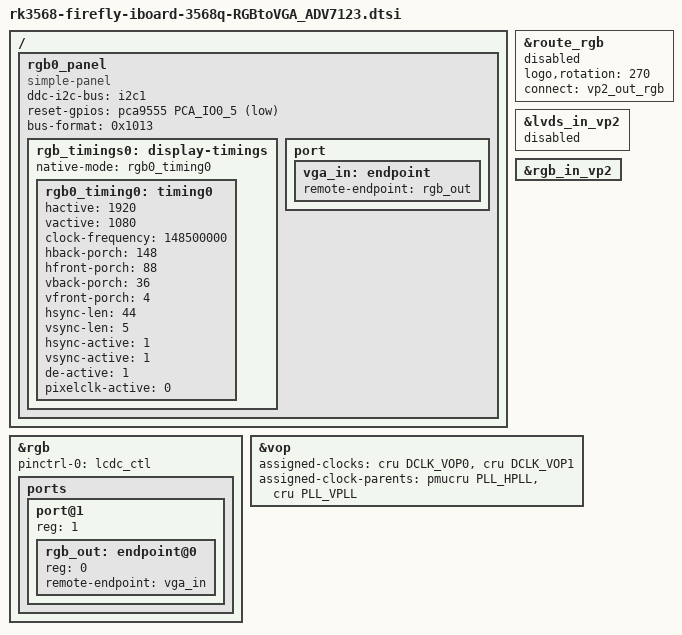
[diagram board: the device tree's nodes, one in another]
// SPDX-License-Identifier: (GPL-2.0+ OR MIT)
/*
 * Copyright (c) 2022 T-chip Firefly. 
 * Support ADV7123 RGB to VGA
 */


/ {

	rgb0_panel {
			status = "okay";
			compatible = "simple-panel";
			ddc-i2c-bus = <&i2c1>;
			//enable-gpios =<&pca9555 PCA_IO0_1 GPIO_ACTIVE_HIGH>;
			reset-gpios = <&pca9555 PCA_IO0_5 GPIO_ACTIVE_LOW>;
			/*	bus-format. default RGB for D23-D16/D15-8/D7-D0. 
			        MEDIA_BUS_FMT_RGB888_1X24,  0x100a
					MEDIA_BUS_FMT_BGR888_1X24,  0x1013
			*/
			bus-format = < 0x1013>;

			/*
				name              refresh     xres    yres    pixclock            h_bp    h_fp    v_bp    v_fp    h_pw    v_pw    polariry    PorI    flag(used for vic)
				{"640x480p@60Hz",   60,         640,    480,    25000000,   48,     16,     33,    10,       96,    2,      0,          0,      1   },
				{"800x600p@60Hz",   60,         800,    600,    40000000,   88,     40,     23,     1,      128,    4,      FB_SYNC_HOR_HIGH_ACT | FB_SYNC_VERT_HIGH_ACT,           0,      0       },
				{"1024x768p@60Hz",  60,         1024,   768,    65000000,   160,    24,     29,     3,      136,    6,      0,          0,      0   },
				{"1280x720p@60Hz",  60,         1280,   720,    74250000,   220,   110,     20,     5,       40,    5,      FB_SYNC_HOR_HIGH_ACT | FB_SYNC_VERT_HIGH_ACT,           0,      0       },
				{"1280x1024p@60Hz", 60,         1280,   1024,   108000000,  248,    48,     38,     1,      112,    3,      FB_SYNC_HOR_HIGH_ACT | FB_SYNC_VERT_HIGH_ACT,           0,      6       },
				{"1366x768p@60Hz",  60,         1366,   768,    85500000,   213,    70,     24,     3,      143,    3,      FB_SYNC_HOR_HIGH_ACT | FB_SYNC_VERT_HIGH_ACT,           0,      0       },
				{"1440x900p@60Hz",  60,         1440,   900,    106500000,  232,    80,     25,     3,      152,    6,      FB_SYNC_VERT_HIGH_ACT,          0,      0   },
				{"1600x900p@60Hz",  60,         1600,   900,    108000000,   96,    24,     96,     1,       80,    3,      FB_SYNC_VERT_HIGH_ACT | FB_SYNC_HOR_HIGH_ACT,           0,      0       },
				{"1680x1050p@60Hz", 60,         1680,   1050,   146200000,  280,    104,    30,     3,      176,    6,      FB_SYNC_VERT_HIGH_ACT,          0,      0   },
				{"1920x1080p@60Hz", 60,         1920,   1080,   148500000,  148,    88,     36,     4,       44,    5,      FB_SYNC_HOR_HIGH_ACT | FB_SYNC_VERT_HIGH_ACT,           0,      0       },
			*/
			rgb_timings0: display-timings {
				native-mode = <&rgb0_timing0>;
				rgb0_timing0: timing0 {
					hactive = <1920>;
					vactive = <1080>;
					clock-frequency = <148500000>;
					hback-porch = <148>; 
					hfront-porch = <88>;
					vback-porch = <36>;
					vfront-porch = <4>;
					hsync-len = <44>;   
					vsync-len = <5>;
					hsync-active = <1>;
					vsync-active = <1>;
					de-active = <1>;
					pixelclk-active = <0>;
				};
			};

			port {
				vga_in: endpoint {
					remote-endpoint = <&rgb_out>;
				};
			};
	};	

};

&route_rgb {
    status = "disabled";
    logo,rotation = <270>; //support rotation 90,180,270
    connect = <&vp2_out_rgb>;
};

&rgb {
	status = "okay";
	pinctrl-names = "default";
	pinctrl-0 = <&lcdc_ctl>;
	ports {
		port@1 {
			reg = <1>;
			#address-cells = <1>;
			#size-cells = <0>;

			rgb_out: endpoint@0 {
				reg = <0>;
				remote-endpoint = <&vga_in>;
			};
		};
	};
};

&lvds_in_vp2 {
	status = "disabled";
};

&rgb_in_vp2 {
	status = "okay";
};


//&route_hdmi {
//    status = "okay";
//    connect = <&vp0_out_hdmi>;
//};

&vop {
	        status = "okay";
			 assigned-clocks = <&cru DCLK_VOP0>, <&cru DCLK_VOP1>;
			        assigned-clock-parents = <&pmucru PLL_HPLL>, <&cru PLL_VPLL>;
};

/delete-node/ &vcc3v3_lcd0_n;
/delete-node/ &vcc3v3_lcd1_n;
